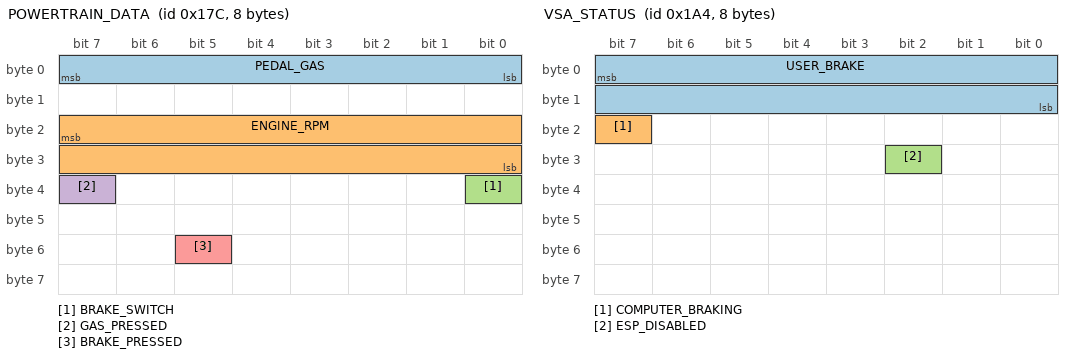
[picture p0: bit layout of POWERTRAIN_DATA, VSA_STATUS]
BO_ 380 POWERTRAIN_DATA: 8 PCM
 SG_ PEDAL_GAS : 7|8@0+ (1,0) [0|255] "" EON
 SG_ ENGINE_RPM : 23|16@0+ (1,0) [0|15000] "rpm" EON
 SG_ BRAKE_SWITCH : 32|1@0+ (1,0) [0|1] "" EON
 SG_ GAS_PRESSED : 39|1@0+ (1,0) [0|1] "" EON
 SG_ BRAKE_PRESSED : 53|1@0+ (1,0) [0|1] "" EON

BO_ 777 CAR_SPEED: 8 PCM
 SG_ ROUGH_CAR_SPEED : 39|16@0+ (0.01,0) [0|65535] "kph" XXX

VAL_ 401 GEAR_SHIFTER 32 "L" 16 "S" 8 "D" 4 "N" 2 "R" 1 "P";
BO_ 401 GEARBOX: 8 PCM
 SG_ GEAR_SHIFTER : 5|6@0+ (1,0) [0|63] "" EON

BO_ 420 VSA_STATUS: 8 VSA
 SG_ USER_BRAKE : 7|16@0+ (1,0) [0|1500] "" EON
 SG_ COMPUTER_BRAKING : 23|1@0+ (1,0) [0|1] "" EON
 SG_ ESP_DISABLED : 26|1@0+ (1,0) [0|1] "" EON

VAL_ 545 ECON_MODE 3 "on" 0 "off" ;
BO_ 545 ECON_STATUS: 6 XXX
 SG_ ECON_MODE : 37|2@0+ (1,0) [0|3] "" EON

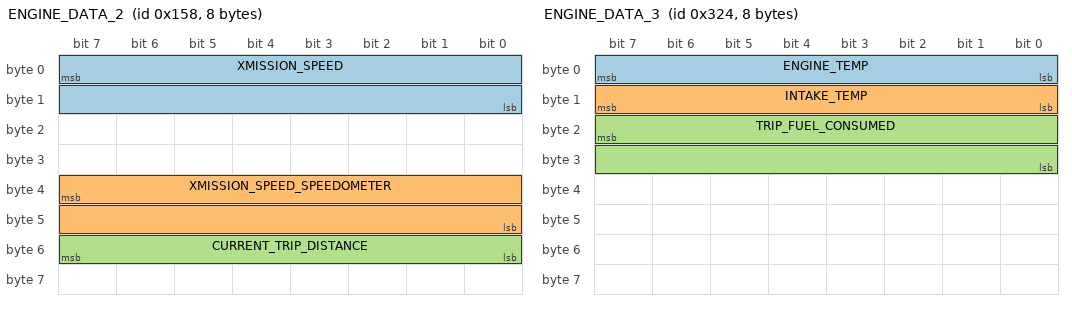
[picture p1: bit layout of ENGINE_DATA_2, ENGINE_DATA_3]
BO_ 344 ENGINE_DATA_2: 8 PCM
 SG_ XMISSION_SPEED : 7|16@0+ (0.01,0) [0|250] "kph" EON
 SG_ XMISSION_SPEED_SPEEDOMETER : 39|16@0+ (0.01,0) [0|250] "kph" EON
 SG_ CURRENT_TRIP_DISTANCE : 55|8@0+ (10,0) [0|2550] "m" XXX

BO_ 804 ENGINE_DATA_3: 8 PCM
 SG_ ENGINE_TEMP : 7|8@0+ (1,-40) [-40|215] "degC" EON
 SG_ INTAKE_TEMP : 15|8@0+ (1,-40) [-40|215] "degC" EON
 SG_ TRIP_FUEL_CONSUMED : 23|16@0+ (0.0001,0) [0|655.35] "mL" EON
